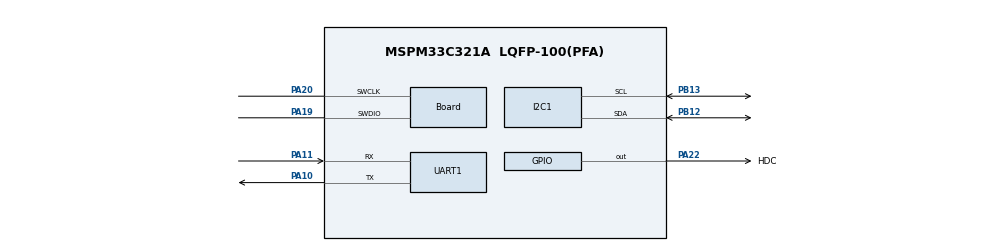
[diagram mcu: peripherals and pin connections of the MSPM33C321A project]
//@cliArgs --device "MSPM33C321A" --package "LQFP-100(PFA)" --part "Default"
//@v2CliArgs --device "MSPM33C321A" --package "LQFP-100(PFA)"
// @cliArgs --board /ti/boards/LP_MSPM33C321A --rtos nortos
// BP-BASSENSORSMKII on the LP-MSPM33C321A. Generated by boards/gen_syscfg.py; edit the table there.
// I2C controller 100 kHz on BoosterPack pins 9 (SCL) and 10 (SDA); four power-switch pins; DRV5055 output on ADC; backchannel UART 115200.
const Board  = scripting.addModule("/ti/driverlib/Board", {}, false);
const GPIO   = scripting.addModule("/ti/driverlib/GPIO", {}, false);
const I2C    = scripting.addModule("/ti/driverlib/I2C", {}, false);
const SYSCTL = scripting.addModule("/ti/driverlib/SYSCTL");
const UART   = scripting.addModule("/ti/driverlib/UART", {}, false);

const I2C1   = I2C.addInstance();
const UART1  = UART.addInstance();
const g_hdc = GPIO.addInstance();
g_hdc.$name = "HDC_PWR";
g_hdc.port = "PORTA";
g_hdc.associatedPins[0].assignedPortSegment = "Upper";
g_hdc.associatedPins[0].assignedPin = "22";
g_hdc.associatedPins[0].$name = "HDC";
g_hdc.associatedPins[0].pin.$assign = "PA22";
g_hdc.associatedPins[0].initialValue = "SET";

Board.peripheral.$assign          = "DEBUGSS";
Board.peripheral.swclkPin.$assign = "PA20";
Board.peripheral.swdioPin.$assign = "PA19";

I2C1.$name                     = "I2C";
I2C1.basicEnableController     = true;
I2C1.basicControllerBusSpeed   = 100000;
I2C1.peripheral.sdaPin.$assign = "PB12";
I2C1.peripheral.sclPin.$assign = "PB13";

UART1.$name                    = "UART_0";
UART1.enableFIFO               = true;
UART1.targetBaudRate           = 115200;
UART1.peripheral.$assign       = "UC12";
UART1.peripheral.rxPin.$assign = "PA11";
UART1.peripheral.txPin.$assign = "PA10";

SYSCTL.forceDefaultClkConfig = true;
SYSCTL.peripheral.$assign    = "SYSCTL";

const ProjectConfig              = scripting.addModule("/ti/project_config/ProjectConfig", {}, false);
ProjectConfig.migrationCondition = true;
